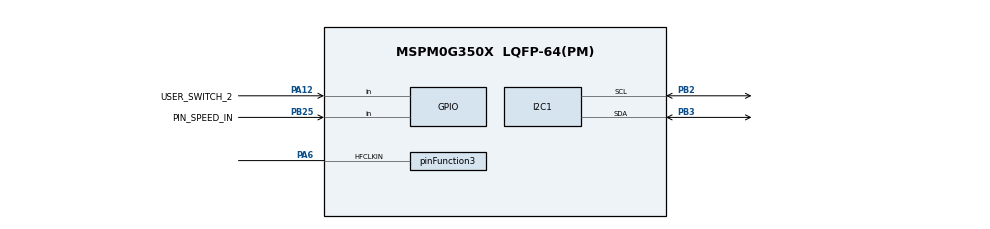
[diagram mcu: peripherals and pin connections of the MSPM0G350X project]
/**
 * @cliArgs --device "MSPM0G350X" --part "Default" --package "LQFP-64(PM)" --product "mspm0_sdk@2.08.00.03"
 * @versions {"tool":"1.26.0+4407"}
 */

/**
 * Import the modules used in this configuration.
 */
const GPIO   = scripting.addModule("/ti/driverlib/GPIO", {}, false);
const GPIO1  = GPIO.addInstance();
const GPIO2  = GPIO.addInstance();
const GPIO3  = GPIO.addInstance();
const GPIO4  = GPIO.addInstance();
const GPIO5  = GPIO.addInstance();
const GPIO6  = GPIO.addInstance();
const GPIO7  = GPIO.addInstance();
const GPIO8  = GPIO.addInstance();
const GPIO9  = GPIO.addInstance();
const GPIO10 = GPIO.addInstance();
const GPIO11 = GPIO.addInstance();
const I2C    = scripting.addModule("/ti/driverlib/I2C", {}, false);
const I2C1   = I2C.addInstance();
const RTC    = scripting.addModule("/ti/driverlib/RTC");
const SYSCTL = scripting.addModule("/ti/driverlib/SYSCTL");
const TIMER  = scripting.addModule("/ti/driverlib/TIMER", {}, false);
const TIMER1 = TIMER.addInstance();
const TIMER2 = TIMER.addInstance();

/**
 * Write custom configuration values to the imported modules.
 */
const mux4       = system.clockTree["EXHFMUX"];
mux4.inputSelect = "EXHFMUX_XTAL";

const pinFunction3                         = system.clockTree["HFCLKEXT"];
pinFunction3.enable                        = true;
pinFunction3.inputFreq                     = 8;
pinFunction3.peripheral.hfclkInPin.$assign = "PA6";

const pinFunction4     = system.clockTree["HFXT"];
pinFunction4.inputFreq = 8;

const pinFunction5     = system.clockTree["LFCLKEXT"];
pinFunction5.inputFreq = 32.768;
pinFunction5.enable    = true;

const pinFunction6     = system.clockTree["LFXT"];
pinFunction6.inputFreq = 32.768;

GPIO1.$name                         = "GPIO_LEDS";
GPIO1.port                          = "PORTA";
GPIO1.associatedPins[0].$name       = "USER_LED_1";
GPIO1.associatedPins[0].assignedPin = "8";

const Board = scripting.addModule("/ti/driverlib/Board", {}, false);

GPIO2.$name                          = "GPIO_5V";
GPIO2.port                           = "PORTB";
GPIO2.associatedPins[0].$name        = "USER_5V";
GPIO2.associatedPins[0].initialValue = "SET";
GPIO2.associatedPins[0].assignedPin  = "0";

GPIO3.$name                          = "GPIO_3_3V";
GPIO3.port                           = "PORTB";
GPIO3.associatedPins[0].$name        = "USER_3_3V";
GPIO3.associatedPins[0].initialValue = "SET";
GPIO3.associatedPins[0].assignedPin  = "1";

GPIO4.$name                         = "GPIO_BL_EN";
GPIO4.port                          = "PORTA";
GPIO4.associatedPins[0].$name       = "USER_BL_EN";
GPIO4.associatedPins[0].assignedPin = "9";

GPIO5.$name                         = "GPIO_dataPin";
GPIO5.port                          = "PORTA";
GPIO5.associatedPins[0].assignedPin = "21";
GPIO5.associatedPins[0].$name       = "PIN_dataPin";

GPIO6.$name                         = "GPIO_clockPin";
GPIO6.port                          = "PORTB";
GPIO6.associatedPins[0].$name       = "PIN_clockPin";
GPIO6.associatedPins[0].assignedPin = "22";

GPIO7.$name                         = "GPIO_latchPin";
GPIO7.port                          = "PORTB";
GPIO7.associatedPins[0].$name       = "PIN_latchPin";
GPIO7.associatedPins[0].assignedPin = "21";

GPIO8.$name                         = "GPIO_G";
GPIO8.port                          = "PORTB";
GPIO8.associatedPins[0].$name       = "PIN_G";
GPIO8.associatedPins[0].assignedPin = "20";

GPIO9.$name                         = "GPIO_CLR";
GPIO9.port                          = "PORTA";
GPIO9.associatedPins[0].$name       = "PIN_CLR";
GPIO9.associatedPins[0].assignedPin = "22";

GPIO10.$name                          = "GPIO_SWITCHES";
GPIO10.associatedPins.create(2);
GPIO10.associatedPins[0].$name        = "USER_SWITCH_1";
GPIO10.associatedPins[0].direction    = "INPUT";
GPIO10.associatedPins[0].assignedPort = "PORTB";
GPIO10.associatedPins[0].assignedPin  = "11";
GPIO10.associatedPins[1].$name        = "USER_SWITCH_2";
GPIO10.associatedPins[1].direction    = "INPUT";
GPIO10.associatedPins[1].pin.$assign  = "PA12";

GPIO11.$name                               = "GPIO_SPEED_IN";
GPIO11.associatedPins[0].$name             = "PIN_SPEED_IN";
GPIO11.associatedPins[0].direction         = "INPUT";
GPIO11.associatedPins[0].assignedPort      = "PORTB";
GPIO11.associatedPins[0].assignedPin       = "25";
GPIO11.associatedPins[0].interruptEn       = true;
GPIO11.associatedPins[0].polarity          = "FALL";
GPIO11.associatedPins[0].interruptPriority = "3";
GPIO11.associatedPins[0].pin.$assign       = "PB25";

I2C1.$name                             = "I2C";
I2C1.basicEnableController             = true;
I2C1.advAnalogGlitchFilter             = "DISABLED";
I2C1.intController                     = ["ARBITRATION_LOST","NACK","TX_DONE"];
I2C1.interruptPriority                 = "1";
I2C1.peripheral.$assign                = "I2C1";
I2C1.peripheral.sdaPin.$assign         = "PB3";
I2C1.peripheral.sclPin.$assign         = "PB2";
I2C1.sdaPinConfig.$name                = "ti_driverlib_gpio_GPIOPinGeneric0";
I2C1.sdaPinConfig.hideOutputInversion  = scripting.forceWrite(false);
I2C1.sdaPinConfig.onlyInternalResistor = scripting.forceWrite(false);
I2C1.sdaPinConfig.passedPeripheralType = scripting.forceWrite("Digital");
I2C1.sclPinConfig.$name                = "ti_driverlib_gpio_GPIOPinGeneric1";
I2C1.sclPinConfig.hideOutputInversion  = scripting.forceWrite(false);
I2C1.sclPinConfig.onlyInternalResistor = scripting.forceWrite(false);
I2C1.sclPinConfig.passedPeripheralType = scripting.forceWrite("Digital");

RTC.calHour = 12;

SYSCTL.forceDefaultClkConfig = true;
SYSCTL.clockTreeEn           = true;
SYSCTL.powerPolicy           = "STANDBY0";

TIMER1.$name              = "TIMER_0";
TIMER1.timerMode          = "PERIODIC";
TIMER1.interrupts         = ["ZERO"];
TIMER1.timerPeriod        = "5ms";
TIMER1.timerClkDiv        = 4;
TIMER1.timerClkPrescale   = 8;
TIMER1.peripheral.$assign = "TIMG0";

TIMER2.timerClkPrescale   = 8;
TIMER2.$name              = "TIMER_65536";
TIMER2.timerClkDiv        = 4;
TIMER2.timerMode          = "PERIODIC";
TIMER2.interruptPriority  = "0";
TIMER2.timerPeriod        = "50ms";
TIMER2.interrupts         = ["LOAD"];
TIMER2.peripheral.$assign = "TIMA0";

/**
 * Pinmux solution for unlocked pins/peripherals. This ensures that minor changes to the automatic solver in a future
 * version of the tool will not impact the pinmux you originally saw.  These lines can be completely deleted in order to
 * re-solve from scratch.
 */
pinFunction3.peripheral.$suggestSolution            = "SYSCTL";
pinFunction5.peripheral.$suggestSolution            = "SYSCTL";
pinFunction5.peripheral.lfclkInPin.$suggestSolution = "PA4";
GPIO1.associatedPins[0].pin.$suggestSolution        = "PA8";
Board.peripheral.$suggestSolution                   = "DEBUGSS";
Board.peripheral.swclkPin.$suggestSolution          = "PA20";
Board.peripheral.swdioPin.$suggestSolution          = "PA19";
GPIO2.associatedPins[0].pin.$suggestSolution        = "PB0";
GPIO3.associatedPins[0].pin.$suggestSolution        = "PB1";
GPIO4.associatedPins[0].pin.$suggestSolution        = "PA9";
GPIO5.associatedPins[0].pin.$suggestSolution        = "PA21";
GPIO6.associatedPins[0].pin.$suggestSolution        = "PB22";
GPIO7.associatedPins[0].pin.$suggestSolution        = "PB21";
GPIO8.associatedPins[0].pin.$suggestSolution        = "PB20";
GPIO9.associatedPins[0].pin.$suggestSolution        = "PA22";
GPIO10.associatedPins[0].pin.$suggestSolution       = "PB11";
RTC.peripheral.$suggestSolution                     = "RTC";
